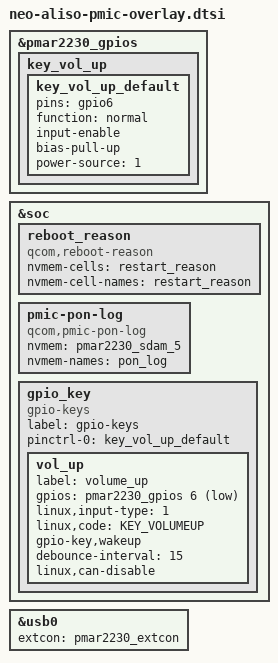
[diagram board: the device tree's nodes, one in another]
#include <dt-bindings/gpio/gpio.h>
#include "pmar2230.dtsi"

&pmar2230_gpios {
	key_vol_up {
		key_vol_up_default: key_vol_up_default {
			pins = "gpio6";
			function = "normal";
			input-enable;
			bias-pull-up;
			power-source = <1>;
		};
	};
};

&soc {
	reboot_reason {
		compatible = "qcom,reboot-reason";
		nvmem-cells = <&restart_reason>;
		nvmem-cell-names = "restart_reason";
	};

	pmic-pon-log {
		compatible = "qcom,pmic-pon-log";
		nvmem = <&pmar2230_sdam_5>;
		nvmem-names = "pon_log";
	};

	gpio_key {
		compatible = "gpio-keys";
		label = "gpio-keys";
		pinctrl-names = "default";
		pinctrl-0 = <&key_vol_up_default>;
		vol_up {
			label = "volume_up";
			gpios = <&pmar2230_gpios 6 GPIO_ACTIVE_LOW>;
			linux,input-type = <1>;
			linux,code = <KEY_VOLUMEUP>;
			gpio-key,wakeup;
			debounce-interval = <15>;
			linux,can-disable;
		};
	};
};

&usb0 {
	extcon = <&pmar2230_extcon>;
};
